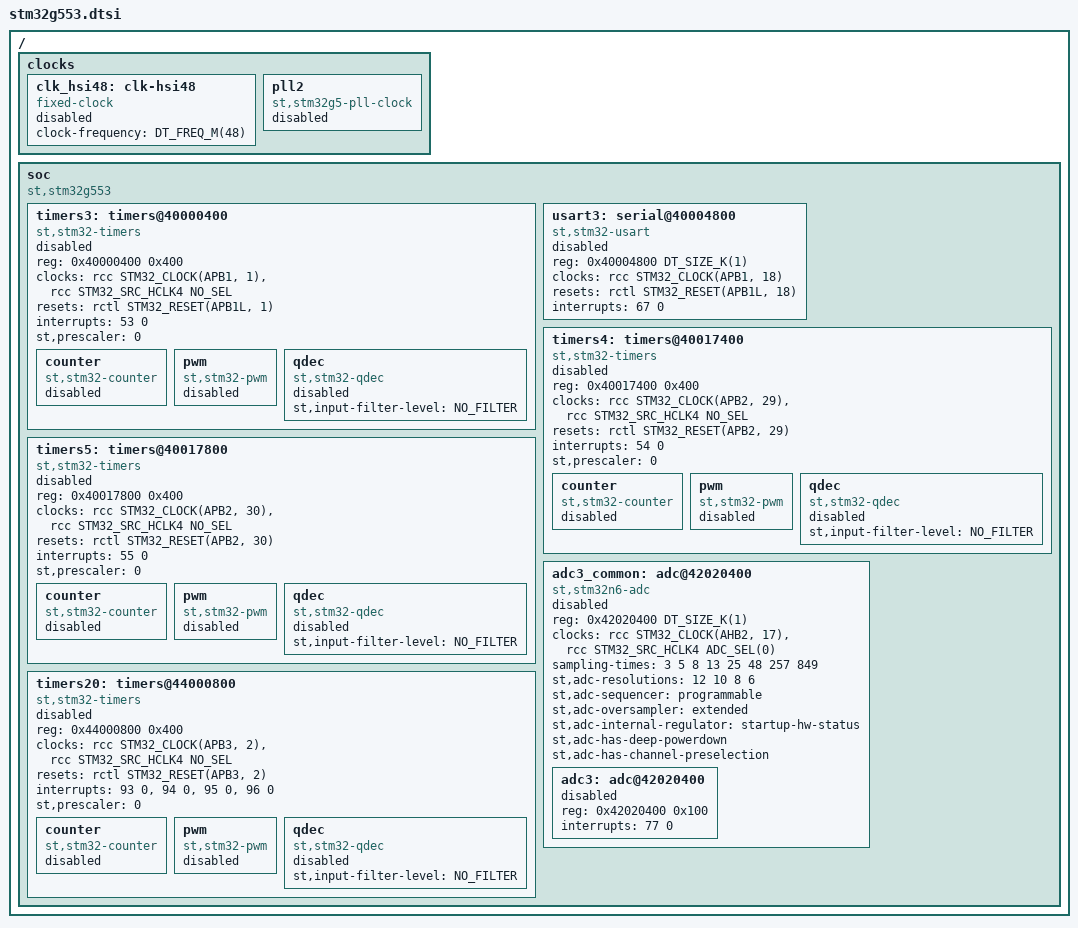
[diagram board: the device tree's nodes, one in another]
/*
 * Copyright (c) 2026 STMicroelectronics
 *
 * SPDX-License-Identifier: Apache-2.0
 */

#include <st/g5/stm32g544.dtsi>

/ {
	clocks {
		clk_hsi48: clk-hsi48 {
			compatible = "fixed-clock";
			#clock-cells = <0>;
			clock-frequency = <DT_FREQ_M(48)>;
			status = "disabled";
		};

		pll2: pll2 {
			compatible = "st,stm32g5-pll-clock", "st,stm32u5-pll-clock";
			#clock-cells = <0>;
			status = "disabled";
		};
	};

	soc {
		compatible = "st,stm32g553", "st,stm32g5", "simple-bus";

		timers3: timers@40000400 {
			compatible = "st,stm32-timers";
			reg = <0x40000400 0x400>;
			clocks = <&rcc STM32_CLOCK(APB1, 1)>,
				 <&rcc STM32_SRC_HCLK4 NO_SEL>;
			resets = <&rctl STM32_RESET(APB1L, 1)>;
			interrupts = <53 0>;
			interrupt-names = "global";
			st,prescaler = <0>;
			status = "disabled";

			counter {
				compatible = "st,stm32-counter";
				status = "disabled";
			};

			pwm {
				compatible = "st,stm32-pwm";
				#pwm-cells = <3>;
				status = "disabled";
			};

			qdec {
				compatible = "st,stm32-qdec";
				st,input-filter-level = <NO_FILTER>;
				status = "disabled";
			};
		};

		usart3: serial@40004800 {
			compatible = "st,stm32-usart", "st,stm32-uart";
			reg = <0x40004800 DT_SIZE_K(1)>;
			clocks = <&rcc STM32_CLOCK(APB1, 18)>;
			resets = <&rctl STM32_RESET(APB1L, 18)>;
			interrupts = <67 0>;
			interrupt-names = "global";
			status = "disabled";
		};

		timers4: timers@40017400 {
			compatible = "st,stm32-timers";
			reg = <0x40017400 0x400>;
			clocks = <&rcc STM32_CLOCK(APB2, 29)>,
				 <&rcc STM32_SRC_HCLK4 NO_SEL>;
			resets = <&rctl STM32_RESET(APB2, 29)>;
			interrupts = <54 0>;
			interrupt-names = "global";
			st,prescaler = <0>;
			status = "disabled";

			counter {
				compatible = "st,stm32-counter";
				status = "disabled";
			};

			pwm {
				compatible = "st,stm32-pwm";
				#pwm-cells = <3>;
				status = "disabled";
			};

			qdec {
				compatible = "st,stm32-qdec";
				st,input-filter-level = <NO_FILTER>;
				status = "disabled";
			};
		};

		timers5: timers@40017800 {
			compatible = "st,stm32-timers";
			reg = <0x40017800 0x400>;
			clocks = <&rcc STM32_CLOCK(APB2, 30)>,
				 <&rcc STM32_SRC_HCLK4 NO_SEL>;
			resets = <&rctl STM32_RESET(APB2, 30)>;
			interrupts = <55 0>;
			interrupt-names = "global";
			st,prescaler = <0>;
			status = "disabled";

			counter {
				compatible = "st,stm32-counter";
				status = "disabled";
			};

			pwm {
				compatible = "st,stm32-pwm";
				#pwm-cells = <3>;
				status = "disabled";
			};

			qdec {
				compatible = "st,stm32-qdec";
				st,input-filter-level = <NO_FILTER>;
				status = "disabled";
			};
		};

		adc3_common: adc@42020400 {
			compatible = "st,stm32n6-adc", "st,stm32-adc";
			reg = <0x42020400 DT_SIZE_K(1)>;
			ranges;
			#address-cells = <1>;
			#size-cells = <1>;
			clocks = <&rcc STM32_CLOCK(AHB2, 17)>,
				 <&rcc STM32_SRC_HCLK4 ADC_SEL(0)>;
			clock-names = "adcx", "adc_ker";
			sampling-times = <3 5 8 13 25 48 257 849>;
			st,adc-resolutions = <12 10 8 6>;
			st,adc-sequencer = "programmable";
			st,adc-oversampler = "extended";
			st,adc-internal-regulator = "startup-hw-status";
			st,adc-has-deep-powerdown;
			st,adc-has-channel-preselection;
			status = "disabled";

			adc3: adc@42020400 {
				reg = <0x42020400 0x100>;
				interrupts = <77 0>;
				interrupt-names = "global";
				#io-channel-cells = <1>;
				status = "disabled";
			};
		};

		timers20: timers@44000800 {
			compatible = "st,stm32-timers";
			reg = <0x44000800 0x400>;
			clocks = <&rcc STM32_CLOCK(APB3, 2)>,
				 <&rcc STM32_SRC_HCLK4 NO_SEL>;
			resets = <&rctl STM32_RESET(APB3, 2)>;
			interrupts = <93 0>, <94 0>, <95 0>, <96 0>;
			interrupt-names = "brk", "up", "trgcom", "cc";
			st,prescaler = <0>;
			status = "disabled";

			counter {
				compatible = "st,stm32-counter";
				status = "disabled";
			};

			pwm {
				compatible = "st,stm32-pwm";
				#pwm-cells = <3>;
				status = "disabled";
			};

			qdec {
				compatible = "st,stm32-qdec";
				st,input-filter-level = <NO_FILTER>;
				status = "disabled";
			};
		};
	};
};
